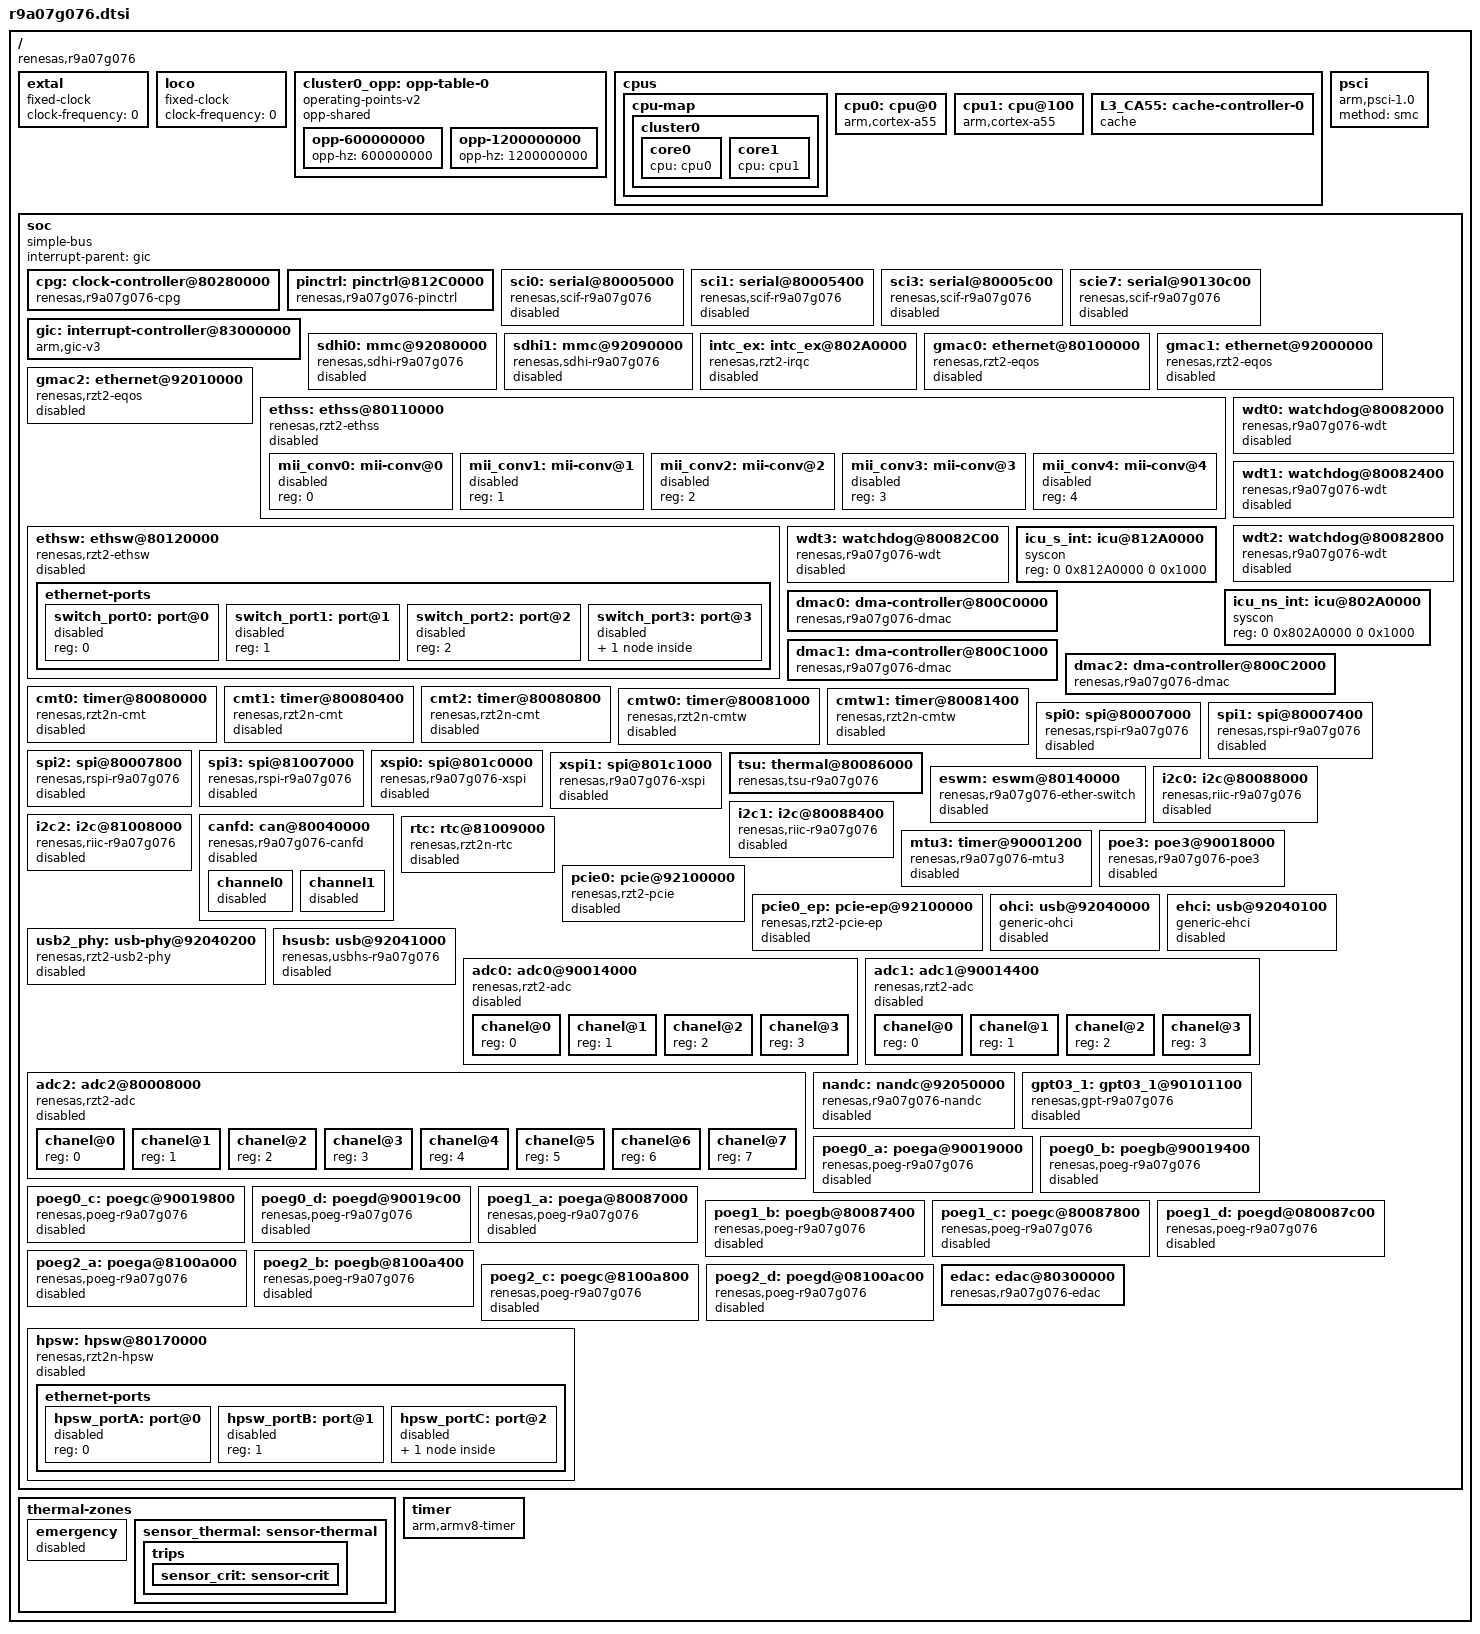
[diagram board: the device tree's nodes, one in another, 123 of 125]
// SPDX-License-Identifier: (GPL-2.0-only OR BSD-2-Clause)
/*
 * Device Tree Source for the RZ/T2N SoC
 *
 * Copyright (C) 2024 Renesas Electronics Corp.
 */

#include <dt-bindings/interrupt-controller/arm-gic.h>
#include <dt-bindings/clock/renesas,r9a07g076-cpg.h>

/ {
	compatible = "renesas,r9a07g076";
	#address-cells = <2>;
	#size-cells = <2>;

	extal: extal {
		compatible = "fixed-clock";
		#clock-cells = <0>;
		/* This value must be overridden by the board */
		clock-frequency = <0>;
	};

	loco: loco {
		compatible = "fixed-clock";
		#clock-cells = <0>;
		/* This value must be overridden by the board */
		clock-frequency = <0>;
	};

	cluster0_opp: opp-table-0 {
		compatible = "operating-points-v2";
		opp-shared;

		opp-600000000 {
			opp-hz = /bits/ 64 <600000000>;
		};
		opp-1200000000 {
			opp-hz = /bits/ 64 <1200000000>;
		};
	};

	cpus {
		#address-cells = <1>;
		#size-cells = <0>;

		cpu-map {
			cluster0 {
				core0 {
					cpu = <&cpu0>;
				};
				core1 {
					cpu = <&cpu1>;
				};
			};
		};

		cpu0: cpu@0 {
			compatible = "arm,cortex-a55";
			reg = <0>;
			device_type = "cpu";
			next-level-cache = <&L3_CA55>;
			enable-method = "psci";
			clocks = <&cpg CPG_MOD R9A07G076_CA55C0_CLK>;
			operating-points-v2 = <&cluster0_opp>;
		};

		cpu1: cpu@100 {
			compatible = "arm,cortex-a55";
			reg = <0x100>;
			device_type = "cpu";
			next-level-cache = <&L3_CA55>;
			enable-method = "psci";
			clocks = <&cpg CPG_MOD R9A07G076_CA55C1_CLK>;
			operating-points-v2 = <&cluster0_opp>;
		};

		L3_CA55: cache-controller-0 {
			compatible = "cache";
			cache-unified;
			cache-size = <0x40000>;
		};
	};

	psci {
		compatible = "arm,psci-1.0", "arm,psci-0.2";
		method = "smc";
	};

	soc: soc {
		compatible = "simple-bus";
		interrupt-parent = <&gic>;
		#address-cells = <2>;
		#size-cells = <2>;
		ranges;

		cpg: clock-controller@80280000 {
			compatible = "renesas,r9a07g076-cpg";
			reg = <0 0x80280000 0 0x1000>,
			      <0 0x81280000 0 0x9000>;
			clocks = <&extal>, <&loco>;
			clock-names = "extal", "loco";
			#clock-cells = <2>;
			#reset-cells = <1>;
			#power-domain-cells = <0>;
		};

		pinctrl: pinctrl@812C0000 {
			compatible = "renesas,r9a07g076-pinctrl";
			reg = <0 0x802C0000 0 0x2000>,
			      <0 0x812C0000 0 0x2000>;
			gpio-controller;
			#gpio-cells = <2>;
			gpio-ranges = <&pinctrl 0 0 201>;
		};

		sci0: serial@80005000 {
			compatible = "renesas,scif-r9a07g076",
				     "renesas,rz-rscif";
			reg = <0 0x80005000 0 0x400>;
			interrupts = <GIC_SPI 465 IRQ_TYPE_LEVEL_HIGH>,
				     <GIC_SPI 466 IRQ_TYPE_EDGE_RISING>,
				     <GIC_SPI 467 IRQ_TYPE_EDGE_RISING>,
				     <GIC_SPI 468 IRQ_TYPE_LEVEL_HIGH>;
			interrupt-names = "eri", "rxi", "txi", "tei";
			clocks = <&cpg CPG_MOD R9A07G076_SCI0_CLK>;
			clock-names = "fck";
			power-domains = <&cpg>;
			status = "disabled";
		};

		sci1: serial@80005400 {
			compatible = "renesas,scif-r9a07g076",
				     "renesas,rz-rscif";
			reg = <0 0x80005400 0 0x400>;
			interrupts = <GIC_SPI 469 IRQ_TYPE_LEVEL_HIGH>,
				     <GIC_SPI 470 IRQ_TYPE_EDGE_RISING>,
				     <GIC_SPI 471 IRQ_TYPE_EDGE_RISING>,
				     <GIC_SPI 472 IRQ_TYPE_LEVEL_HIGH>;
			interrupt-names = "eri", "rxi", "txi", "tei";
			clocks = <&cpg CPG_MOD R9A07G076_SCI1_CLK>;
			clock-names = "fck";
			power-domains = <&cpg>;
			status = "disabled";
		};

		sci3: serial@80005c00 {
			compatible = "renesas,scif-r9a07g076",
				     "renesas,rz-rscif";
			reg = <0 0x80005c00 0 0x400>;
			interrupts = <GIC_SPI 477 IRQ_TYPE_LEVEL_HIGH>,
				     <GIC_SPI 478 IRQ_TYPE_EDGE_RISING>,
				     <GIC_SPI 479 IRQ_TYPE_EDGE_RISING>,
				     <GIC_SPI 480 IRQ_TYPE_LEVEL_HIGH>;
			interrupt-names = "eri", "rxi", "txi", "tei";
			clocks = <&cpg CPG_MOD R9A07G076_SCI3_CLK>;
			clock-names = "fck";
			power-domains = <&cpg>;
			status = "disabled";
		};

		scie7: serial@90130c00 {
			compatible = "renesas,scif-r9a07g076",
				     "renesas,rz-rscif";
			reg = <0 0x90130c00 0 0x400>;
			interrupts = <GIC_SPI 600 IRQ_TYPE_LEVEL_HIGH>,
				     <GIC_SPI 601 IRQ_TYPE_EDGE_RISING>,
				     <GIC_SPI 602 IRQ_TYPE_EDGE_RISING>,
				     <GIC_SPI 603 IRQ_TYPE_LEVEL_HIGH>;
			interrupt-names = "eri", "rxi", "txi", "tei";
			clocks = <&cpg CPG_MOD R9A07G076_SCIE7_CLK>;
			clock-names = "fck";
			power-domains = <&cpg>;
			status = "disabled";
		};

		gic: interrupt-controller@83000000 {
			compatible = "arm,gic-v3";
			#interrupt-cells = <3>;
			#address-cells = <0>;
			interrupt-controller;
			reg = <0x0 0x83000000 0 0x40000>,
			      <0x0 0x83040000 0 0x160000>;
			interrupts = <GIC_PPI 9 IRQ_TYPE_LEVEL_LOW>;
		};

		sdhi0: mmc@92080000 {
			compatible = "renesas,sdhi-r9a07g076";
			reg = <0x0 0x92080000 0 0x10000>,
			      <0x0 0x8129B000 0 0x4>;
			interrupts = <GIC_SPI 604 IRQ_TYPE_LEVEL_HIGH>,
				     <GIC_SPI 605 IRQ_TYPE_LEVEL_HIGH>;
			clocks = <&cpg CPG_MOD R9A07G076_SDHI0_CLK>;
			clock-names = "clk";
			power-domains = <&cpg>;
			status = "disabled";
		};

		sdhi1: mmc@92090000 {
			compatible = "renesas,sdhi-r9a07g076";
			reg = <0x0 0x92090000 0 0x10000>,
			      <0x0 0x8129B004 0 0x4>;
			interrupts = <GIC_SPI 606 IRQ_TYPE_LEVEL_HIGH>,
				     <GIC_SPI 607 IRQ_TYPE_LEVEL_HIGH>;
			clocks = <&cpg CPG_MOD R9A07G076_SDHI1_CLK>;
			clock-names = "clk";
			power-domains = <&cpg>;
			status = "disabled";
		};

		intc_ex: intc_ex@802A0000 {
			compatible = "renesas,rzt2-irqc";
			#interrupt-cells = <2>;
			interrupt-controller;
			reg = <0x0 0x802A0000 0 0x1000>,
			      <0x0 0x812A0000 0 0x1000>;
			interrupts = <GIC_SPI 16 IRQ_TYPE_EDGE_RISING>,
				     <GIC_SPI 17 IRQ_TYPE_EDGE_RISING>,
				     <GIC_SPI 18 IRQ_TYPE_EDGE_RISING>,
				     <GIC_SPI 19 IRQ_TYPE_EDGE_RISING>,
				     <GIC_SPI 20 IRQ_TYPE_EDGE_RISING>,
				     <GIC_SPI 21 IRQ_TYPE_EDGE_RISING>,
				     <GIC_SPI 22 IRQ_TYPE_EDGE_RISING>,
				     <GIC_SPI 23 IRQ_TYPE_EDGE_RISING>,
				     <GIC_SPI 24 IRQ_TYPE_EDGE_RISING>,
				     <GIC_SPI 25 IRQ_TYPE_EDGE_RISING>,
				     <GIC_SPI 26 IRQ_TYPE_EDGE_RISING>,
				     <GIC_SPI 27 IRQ_TYPE_EDGE_RISING>,
				     <GIC_SPI 28 IRQ_TYPE_EDGE_RISING>,
				     <GIC_SPI 29 IRQ_TYPE_EDGE_RISING>,
				     <GIC_SPI 30 IRQ_TYPE_EDGE_RISING>,
				     <GIC_SPI 31 IRQ_TYPE_EDGE_RISING>;
			interrupt-names = "irq0", "irq1", "irq2", "irq3",
					  "irq4", "irq5", "irq6", "irq7",
					  "irq8", "irq9", "irq10", "irq11",
					  "irq12", "irq13", "irq14", "irq15";
			status = "disabled";
		};

		gmac0: ethernet@80100000 {
			compatible = "renesas,rzt2-eqos",
				     "snps,dwc-qos-ethernet-4.10";
			reg = <0 0x80100000 0 0x10000>;
			interrupts = <GIC_SPI 368 IRQ_TYPE_LEVEL_HIGH>,
				     <GIC_SPI 370 IRQ_TYPE_LEVEL_HIGH>,
				     <GIC_SPI 369 IRQ_TYPE_LEVEL_HIGH>;
			interrupt-names = "macirq", "eth_wake_irq", "eth_lpi";
			clocks = <&cpg CPG_MOD R9A07G076_GMAC0_CLK>;
			clock-names = "clk";
			ethsw_ptp_timer = <0 0>; /* GMAC0 PTP use ETHSW timer 0*/
			resets = <&cpg R9A07G076_GMAC0_PCLKH_RST>,
				 <&cpg R9A07G076_GMAC0_PCLKM_RST>;
			reset-names = "reset_h", "reset_m";
			#address-cells = <1>;
			#size-cells = <0>;
			status = "disabled";
			snps,write-requests = <15>;
			snps,read-requests = <15>;
			snps,burst-map = <0x7>;
		};

		gmac1: ethernet@92000000 {
			compatible = "renesas,rzt2-eqos",
				     "snps,dwc-qos-ethernet-4.10";
			reg = <0 0x92000000 0 0x10000>;
			interrupts = <GIC_SPI 387 IRQ_TYPE_LEVEL_HIGH>,
				     <GIC_SPI 389 IRQ_TYPE_LEVEL_HIGH>,
				     <GIC_SPI 388 IRQ_TYPE_LEVEL_HIGH>;
			interrupt-names = "macirq", "eth_wake_irq", "eth_lpi";
			clocks = <&cpg CPG_MOD R9A07G076_GMAC1_CLK>;
			clock-names = "clk";
			ethsw_ptp_timer = <1 0>; /* GMAC1 PTP use ETHSW timer 0*/
			resets = <&cpg R9A07G076_GMAC1_PCLKAH_RST>,
				 <&cpg R9A07G076_GMAC1_PCLKAM_RST>;
			reset-names = "reset_h", "reset_m";
			#address-cells = <1>;
			#size-cells = <0>;
			status = "disabled";
			snps,write-requests = <15>;
			snps,read-requests = <15>;
			snps,burst-map = <0x7>;
		};

		gmac2: ethernet@92010000 {
			compatible = "renesas,rzt2-eqos",
				     "snps,dwc-qos-ethernet-4.10";
			reg = <0 0x92010000 0 0x10000>;
			interrupts = <GIC_SPI 406 IRQ_TYPE_LEVEL_HIGH>,
				     <GIC_SPI 408 IRQ_TYPE_LEVEL_HIGH>,
				     <GIC_SPI 407 IRQ_TYPE_LEVEL_HIGH>;
			interrupt-names = "macirq", "eth_wake_irq", "eth_lpi";
			clocks = <&cpg CPG_MOD R9A07G076_GMAC2_CLK>;
			clock-names = "clk";
			ethsw_ptp_timer = <2 0>; /* GMAC2 PTP use ETHSW timer 0*/
			resets = <&cpg R9A07G076_GMAC2_PCLKAH_RST>,
				 <&cpg R9A07G076_GMAC2_PCLKAM_RST>;
			reset-names = "reset_h", "reset_m";
			#address-cells = <1>;
			#size-cells = <0>;
			status = "disabled";
			snps,write-requests = <15>;
			snps,read-requests = <15>;
			snps,burst-map = <0x7>;
		};

		ethss: ethss@80110000 {
			compatible = "renesas,rzt2-ethss";
			#address-cells = <1>;
			#size-cells = <0>;
			reg =  <0 0x80110000 0 0x10000>;
			clocks = <&cpg CPG_MOD R9A07G076_ETHSS_CLK>;
			resets = <&cpg R9A07G076_ETHSS_RST>,
				 <&cpg R9A07G076_MII_RST>;
			reset-names = "reset_ethss", "reset_conv";
			power-domains = <&cpg>;
			status = "disabled";

			mii_conv0: mii-conv@0 {
				reg = <0>;
				status = "disabled";
			};

			mii_conv1: mii-conv@1 {
				reg = <1>;
				status = "disabled";
			};

			mii_conv2: mii-conv@2 {
				reg = <2>;
				status = "disabled";
			};

			mii_conv3: mii-conv@3 {
				reg = <3>;
				status = "disabled";
			};

			mii_conv4: mii-conv@4 {
				reg = <4>;
				status = "disabled";
			};
		};

		ethsw: ethsw@80120000 {
			compatible = "renesas,rzt2-ethsw";
			reg =  <0 0x80120000 0 0x10000>;
			clocks = <&cpg CPG_MOD R9A07G076_ETHSW_CLK>;
			resets = <&cpg R9A07G076_ETHSW_RST>;
			power-domains = <&cpg>;
			interrupts = <GIC_SPI 425 IRQ_TYPE_LEVEL_HIGH>;
			interrupt-names = "ethsw_intr";
			ethsw_ptp_timer = <0>;	/* ETHSW PTP use ETHSW timer 0*/
			status = "disabled";

			ethernet-ports {
				#address-cells = <1>;
				#size-cells = <0>;

				switch_port0: port@0 {
					reg = <0>;
					status = "disabled";
				};

				switch_port1: port@1 {
					reg = <1>;
					status = "disabled";
				};

				switch_port2: port@2 {
					reg = <2>;
					status = "disabled";
				};

				switch_port3: port@3 {
					reg = <3>;
					ethernet = <&gmac0>;
					label = "cpu";
					phy-mode = "internal";
					status = "disabled";
					fixed-link {
						speed = <1000>;
						full-duplex;
					};
				};
			};
		};

		wdt0: watchdog@80082000 {
			compatible = "renesas,r9a07g076-wdt";
			reg = <0 0x80082000 0 0x400>,
			      <0 0x81295100 0 0x04>;
			reg-names = "wdt", "dbg";
			clocks = <&cpg CPG_CORE R9A07G076_PCLKL>;
			clock-names = "pclkl";
			power-domains = <&cpg>;
			renesas,syscon-perierr-error = <&icu_ns_int>;
			status = "disabled";
		};

		wdt1: watchdog@80082400 {
			compatible = "renesas,r9a07g076-wdt";
			reg = <0 0x80082400 0 0x400>,
			      <0 0x81295104 0 0x04>;
			reg-names = "wdt", "dbg";
			clocks = <&cpg CPG_CORE R9A07G076_PCLKL>;
			clock-names = "pclkl";
			power-domains = <&cpg>;
			renesas,syscon-perierr-error = <&icu_ns_int>;
			status = "disabled";
		};

		wdt2: watchdog@80082800 {
			compatible = "renesas,r9a07g076-wdt";
			reg = <0 0x80082800 0 0x400>,
			      <0 0x81295108 0 0x04>;
			reg-names = "wdt", "dbg";
			clocks = <&cpg CPG_CORE R9A07G076_PCLKL>;
			clock-names = "pclkl";
			power-domains = <&cpg>;
			renesas,syscon-perierr-error = <&icu_ns_int>;
			status = "disabled";
		};

		wdt3: watchdog@80082C00 {
			compatible = "renesas,r9a07g076-wdt";
			reg = <0 0x80082C00 0 0x400>,
			      <0 0x8129510C 0 0x04>;
			reg-names = "wdt", "dbg";
			clocks = <&cpg CPG_CORE R9A07G076_PCLKL>;
			clock-names = "pclkl";
			power-domains = <&cpg>;
			renesas,syscon-perierr-error = <&icu_ns_int>;
			status = "disabled";
		};

		icu_s_int: icu@812A0000 {
			compatible = "syscon";
			reg = <0 0x812A0000 0 0x1000>;
		};

		icu_ns_int: icu@802A0000 {
			compatible = "syscon";
			reg = <0 0x802A0000 0 0x1000>;
		};

		dmac0: dma-controller@800C0000 {
			compatible = "renesas,r9a07g076-dmac";
			reg = <0 0x800c0000 0 0x1000>;
			interrupts = <GIC_SPI 32 IRQ_TYPE_EDGE_RISING>,
				     <GIC_SPI 33 IRQ_TYPE_EDGE_RISING>,
				     <GIC_SPI 34 IRQ_TYPE_EDGE_RISING>,
				     <GIC_SPI 35 IRQ_TYPE_EDGE_RISING>,
				     <GIC_SPI 36 IRQ_TYPE_EDGE_RISING>,
				     <GIC_SPI 37 IRQ_TYPE_EDGE_RISING>,
				     <GIC_SPI 38 IRQ_TYPE_EDGE_RISING>,
				     <GIC_SPI 39 IRQ_TYPE_EDGE_RISING>,
				     <GIC_SPI 40 IRQ_TYPE_EDGE_RISING>,
				     <GIC_SPI 41 IRQ_TYPE_EDGE_RISING>,
				     <GIC_SPI 42 IRQ_TYPE_EDGE_RISING>,
				     <GIC_SPI 43 IRQ_TYPE_EDGE_RISING>,
				     <GIC_SPI 44 IRQ_TYPE_EDGE_RISING>,
				     <GIC_SPI 45 IRQ_TYPE_EDGE_RISING>,
				     <GIC_SPI 46 IRQ_TYPE_EDGE_RISING>,
				     <GIC_SPI 47 IRQ_TYPE_EDGE_RISING>;
			interrupt-names = "ch0", "ch1", "ch2", "ch3",
					  "ch4", "ch5", "ch6", "ch7",
					  "ch8", "ch9", "ch10", "ch11",
					  "ch12", "ch13", "ch14", "ch15";
			#dma-cells = <1>;
			dma-channels = <16>;
			renesas,icu = <&intc_ex 0>;
		};

		dmac1: dma-controller@800C1000 {
			compatible = "renesas,r9a07g076-dmac";
			reg = <0 0x800c1000 0 0x1000>;
			interrupts = <GIC_SPI 48 IRQ_TYPE_EDGE_RISING>,
				     <GIC_SPI 49 IRQ_TYPE_EDGE_RISING>,
				     <GIC_SPI 50 IRQ_TYPE_EDGE_RISING>,
				     <GIC_SPI 51 IRQ_TYPE_EDGE_RISING>,
				     <GIC_SPI 52 IRQ_TYPE_EDGE_RISING>,
				     <GIC_SPI 53 IRQ_TYPE_EDGE_RISING>,
				     <GIC_SPI 54 IRQ_TYPE_EDGE_RISING>,
				     <GIC_SPI 55 IRQ_TYPE_EDGE_RISING>,
				     <GIC_SPI 56 IRQ_TYPE_EDGE_RISING>,
				     <GIC_SPI 57 IRQ_TYPE_EDGE_RISING>,
				     <GIC_SPI 58 IRQ_TYPE_EDGE_RISING>,
				     <GIC_SPI 59 IRQ_TYPE_EDGE_RISING>,
				     <GIC_SPI 60 IRQ_TYPE_EDGE_RISING>,
				     <GIC_SPI 61 IRQ_TYPE_EDGE_RISING>,
				     <GIC_SPI 62 IRQ_TYPE_EDGE_RISING>,
				     <GIC_SPI 63 IRQ_TYPE_EDGE_RISING>;
			interrupt-names = "ch0", "ch1", "ch2", "ch3",
					  "ch4", "ch5", "ch6", "ch7",
					  "ch8", "ch9", "ch10", "ch11",
					  "ch12", "ch13", "ch14", "ch15";
			#dma-cells = <1>;
			dma-channels = <16>;
			renesas,icu = <&intc_ex 1>;
		};

		dmac2: dma-controller@800C2000 {
			compatible = "renesas,r9a07g076-dmac";
			reg = <0 0x800c2000 0 0x1000>;
			interrupts = <GIC_SPI 64 IRQ_TYPE_EDGE_RISING>,
				     <GIC_SPI 65 IRQ_TYPE_EDGE_RISING>,
				     <GIC_SPI 66 IRQ_TYPE_EDGE_RISING>,
				     <GIC_SPI 67 IRQ_TYPE_EDGE_RISING>,
				     <GIC_SPI 68 IRQ_TYPE_EDGE_RISING>,
				     <GIC_SPI 69 IRQ_TYPE_EDGE_RISING>,
				     <GIC_SPI 70 IRQ_TYPE_EDGE_RISING>,
				     <GIC_SPI 71 IRQ_TYPE_EDGE_RISING>,
				     <GIC_SPI 72 IRQ_TYPE_EDGE_RISING>,
				     <GIC_SPI 73 IRQ_TYPE_EDGE_RISING>,
				     <GIC_SPI 74 IRQ_TYPE_EDGE_RISING>,
				     <GIC_SPI 75 IRQ_TYPE_EDGE_RISING>,
				     <GIC_SPI 76 IRQ_TYPE_EDGE_RISING>,
				     <GIC_SPI 77 IRQ_TYPE_EDGE_RISING>,
				     <GIC_SPI 78 IRQ_TYPE_EDGE_RISING>,
				     <GIC_SPI 79 IRQ_TYPE_EDGE_RISING>;
			interrupt-names = "ch0", "ch1", "ch2", "ch3",
					  "ch4", "ch5", "ch6", "ch7",
					  "ch8", "ch9", "ch10", "ch11",
					  "ch12", "ch13", "ch14", "ch15";
			#dma-cells = <1>;
			dma-channels = <16>;
			renesas,icu = <&intc_ex 2>;
		};

		cmt0: timer@80080000 {
			compatible = "renesas,rzt2n-cmt";
			reg = <0 0x80080000 0 0x400>;
			interrupts = <GIC_SPI 349 IRQ_TYPE_EDGE_RISING>,
				     <GIC_SPI 350 IRQ_TYPE_EDGE_RISING>;
			clocks = <&cpg CPG_MOD R9A07G076_CMT0_CLK>;
			clock-names = "fck0";
			power-domains = <&cpg>;
			status = "disabled";
		};

		cmt1: timer@80080400 {
			compatible = "renesas,rzt2n-cmt";
			reg = <0 0x80080400 0 0x400>;
			interrupts = <GIC_SPI 351 IRQ_TYPE_EDGE_RISING>,
				     <GIC_SPI 352 IRQ_TYPE_EDGE_RISING>;
			clocks = <&cpg CPG_MOD R9A07G076_CMT1_CLK>;
			clock-names = "fck0";
			power-domains = <&cpg>;
			status = "disabled";
		};

		cmt2: timer@80080800 {
			compatible = "renesas,rzt2n-cmt";
			reg = <0 0x80080800 0 0x400>;
			interrupts = <GIC_SPI 353 IRQ_TYPE_EDGE_RISING>,
				     <GIC_SPI 354 IRQ_TYPE_EDGE_RISING>;
			clocks = <&cpg CPG_MOD R9A07G076_CMT2_CLK>;
			clock-names = "fck0";
			power-domains = <&cpg>;
			status = "disabled";
		};

		cmtw0: timer@80081000 {
			compatible = "renesas,rzt2n-cmtw";
			reg = <0 0x80081000 0 0x400>;
			interrupts = <GIC_SPI 355 IRQ_TYPE_EDGE_RISING>;
			clocks = <&cpg CPG_MOD R9A07G076_CMTW0_CLK>;
			clock-names = "fck0";
			power-domains = <&cpg>;
			status = "disabled";
		};

		cmtw1: timer@80081400 {
			compatible = "renesas,rzt2n-cmtw";
			reg = <0 0x80081400 0 0x400>;
			interrupts = <GIC_SPI 360 IRQ_TYPE_EDGE_RISING>;
			clocks = <&cpg CPG_MOD R9A07G076_CMTW1_CLK>;
			clock-names = "fck0";
			power-domains = <&cpg>;
			status = "disabled";
		};

		spi0: spi@80007000 {
			compatible = "renesas,rspi-r9a07g076";
			reg = <0 0x80007000 0 0x100>;
			interrupts = <GIC_SPI 509 IRQ_TYPE_EDGE_RISING>,
				     <GIC_SPI 510 IRQ_TYPE_EDGE_RISING>,
				     <GIC_SPI 512 IRQ_TYPE_LEVEL_HIGH>;
			interrupt-names = "rx", "tx", "error";
			clocks = <&cpg CPG_MOD R9A07G076_SPI0_CLK>;
			power-domains = <&cpg>;
			num-cs = <1>;
			dmas = <&dmac0 0x25FE>, <&dmac0 0x25FD>;
			dma-names = "tx", "rx";
			#address-cells = <1>;
			#size-cells = <0>;
			status = "disabled";
		};

		spi1: spi@80007400 {
			compatible = "renesas,rspi-r9a07g076";
			reg = <0 0x80007400 0 0x100>;
			interrupts = <GIC_SPI 514 IRQ_TYPE_EDGE_RISING>,
				     <GIC_SPI 515 IRQ_TYPE_EDGE_RISING>,
				     <GIC_SPI 517 IRQ_TYPE_LEVEL_HIGH>;
			interrupt-names = "rx", "tx", "error";
			clocks = <&cpg CPG_MOD R9A07G076_SPI1_CLK>;
			power-domains = <&cpg>;
			num-cs = <1>;
			dmas = <&dmac0 0x2603>, <&dmac0 0x2602>;
			dma-names = "tx", "rx";
			#address-cells = <1>;
			#size-cells = <0>;
			status = "disabled";
		};

		spi2: spi@80007800 {
			compatible = "renesas,rspi-r9a07g076";
			reg = <0 0x80007800 0 0x100>;
			interrupts = <GIC_SPI 519 IRQ_TYPE_EDGE_RISING>,
				     <GIC_SPI 520 IRQ_TYPE_EDGE_RISING>,
				     <GIC_SPI 522 IRQ_TYPE_LEVEL_HIGH>;
			interrupt-names = "rx", "tx", "error";
			clocks = <&cpg CPG_MOD R9A07G076_SPI2_CLK>;
			power-domains = <&cpg>;
			num-cs = <1>;
			dmas = <&dmac0 0x2608>, <&dmac0 0x2607>;
			dma-names = "tx", "rx";
			#address-cells = <1>;
			#size-cells = <0>;
			status = "disabled";
		};

		spi3: spi@81007000 {
			compatible = "renesas,rspi-r9a07g076";
			reg = <0 0x81007000 0 0x100>;
			interrupts = <GIC_SPI 524 IRQ_TYPE_EDGE_RISING>,
				     <GIC_SPI 525 IRQ_TYPE_EDGE_RISING>,
				     <GIC_SPI 527 IRQ_TYPE_LEVEL_HIGH>;
			interrupt-names = "rx", "tx", "error";
			clocks = <&cpg CPG_MOD R9A07G076_SPI3_CLK>;
			power-domains = <&cpg>;
			num-cs = <1>;
			#address-cells = <1>;
			#size-cells = <0>;
			status = "disabled";
		};

		xspi0: spi@801c0000 {
			compatible = "renesas,r9a07g076-xspi",
				     "renesas,r9a09g047-xspi";
			reg = <0 0x801c0000 0 0x1000>,
			      <0 0x40000000 0 0x10000000>;
			reg-names = "regs", "dirmap";
			resets = <&cpg R9A07G076_xSPI0_RST>;
			power-domains = <&cpg>;
			#address-cells = <1>;
			#size-cells = <0>;
			status = "disabled";
		};

		xspi1: spi@801c1000 {
			compatible = "renesas,r9a07g076-xspi",
				     "renesas,r9a09g047-xspi";
			reg = <0 0x801c1000 0 0x1000>,
			      <0 0x50000000 0 0x10000000>;
			reg-names = "regs", "dirmap";
			resets = <&cpg R9A07G076_xSPI1_RST>;
			power-domains = <&cpg>;
			#address-cells = <1>;
			#size-cells = <0>;
			status = "disabled";
		};

		tsu: thermal@80086000 {
			compatible = "renesas,tsu-r9a07g076";
			reg = <0 0x80086000 0 0x1000>;
			clocks = <&cpg CPG_MOD R9A07G076_TSU_CLK>;
			clock-names = "tsu_clk";
			#thermal-sensor-cells = <1>;
		};

		eswm: eswm@80140000 {
			compatible = "renesas,r9a07g076-ether-switch";
			reg = <0 0x80140000 0 0x30000>;
			reg-names = "base";
			interrupts = <GIC_SPI 456 IRQ_TYPE_LEVEL_HIGH>,
				     <GIC_SPI 457 IRQ_TYPE_LEVEL_HIGH>,
				     <GIC_SPI 458 IRQ_TYPE_LEVEL_HIGH>,
				     <GIC_SPI 459 IRQ_TYPE_LEVEL_HIGH>,
				     <GIC_SPI 460 IRQ_TYPE_LEVEL_HIGH>,
				     <GIC_SPI 630 IRQ_TYPE_LEVEL_HIGH>,
				     <GIC_SPI 631 IRQ_TYPE_LEVEL_HIGH>,
				     <GIC_SPI 632 IRQ_TYPE_LEVEL_HIGH>,
				     <GIC_SPI 633 IRQ_TYPE_LEVEL_HIGH>,
				     <GIC_SPI 634 IRQ_TYPE_LEVEL_HIGH>,
				     <GIC_SPI 635 IRQ_TYPE_LEVEL_HIGH>,
				     <GIC_SPI 636 IRQ_TYPE_LEVEL_HIGH>,
				     <GIC_SPI 637 IRQ_TYPE_LEVEL_HIGH>,
				     <GIC_SPI 638 IRQ_TYPE_LEVEL_HIGH>,
				     <GIC_SPI 639 IRQ_TYPE_LEVEL_HIGH>;
			interrupt-names = "gptp", "mfwd",
					  "coma", "eth0",
					  "eth1", "gwca0_rxtx0",
					  "gwca0_rxtx1", "gwca0_rxtx2",
					  "gwca0_rxtx3", "gwca0_rxtx4",
					  "gwca0_rxtx5", "gwca0_rxtx6",
					  "gwca0_rxtx7", "gwca0_rxts0",
					  "gwca0_rxts1";
			#address-cells = <1>;
			#size-cells = <0>;
			eswm_ptp_timer = <1>;	/*ESWM PTP use ESWM timer 1*/
			clocks = <&cpg CPG_MOD R9A07G076_ESWM_CLK>;
			resets = <&cpg R9A07G076_ESWM_RST>;
			power-domains = <&cpg>;
			status = "disabled";
		};

		i2c0: i2c@80088000 {
			#address-cells = <1>;
			#size-cells = <0>;
			compatible = "renesas,riic-r9a07g076";
			reg = <0 0x80088000 0 0x20>;
			interrupts = <GIC_SPI 489 IRQ_TYPE_LEVEL_HIGH>,
				     <GIC_SPI 490 IRQ_TYPE_EDGE_RISING>,
				     <GIC_SPI 491 IRQ_TYPE_EDGE_RISING>,
				     <GIC_SPI 492 IRQ_TYPE_LEVEL_HIGH>;
			interrupt-names = "eei", "rxi", "txi", "tei";
			clocks = <&cpg CPG_MOD R9A07G076_IIC0_CLK>;
			clock-frequency = <100000>;
			power-domains = <&cpg>;
			status = "disabled";
		};

		i2c1: i2c@80088400 {
			#address-cells = <1>;
			#size-cells = <0>;
			compatible = "renesas,riic-r9a07g076";
			reg = <0 0x80088400 0 0x20>;
			interrupts = <GIC_SPI 493 IRQ_TYPE_LEVEL_HIGH>,
				     <GIC_SPI 494 IRQ_TYPE_EDGE_RISING>,
				     <GIC_SPI 495 IRQ_TYPE_EDGE_RISING>,
				     <GIC_SPI 496 IRQ_TYPE_LEVEL_HIGH>;
			interrupt-names = "eei", "rxi", "txi", "tei";
			clocks = <&cpg CPG_MOD R9A07G076_IIC1_CLK>;
			clock-frequency = <100000>;
			power-domains = <&cpg>;
			status = "disabled";
		};

		i2c2: i2c@81008000 {
			#address-cells = <1>;
			#size-cells = <0>;
			compatible = "renesas,riic-r9a07g076";
			reg = <0 0x81008000 0 0x20>;
			interrupts = <GIC_SPI 497 IRQ_TYPE_LEVEL_HIGH>,
				     <GIC_SPI 498 IRQ_TYPE_EDGE_RISING>,
				     <GIC_SPI 499 IRQ_TYPE_EDGE_RISING>,
				     <GIC_SPI 500 IRQ_TYPE_LEVEL_HIGH>;
			interrupt-names = "eei", "rxi", "txi", "tei";
			clocks = <&cpg CPG_MOD R9A07G076_IIC2_CLK>;
			clock-frequency = <100000>;
			power-domains = <&cpg>;
			status = "disabled";
		};

		canfd: can@80040000 {
			compatible = "renesas,r9a07g076-canfd";
			reg = <0 0x80040000 0 0x20000>;
			interrupts =	<GIC_SPI 501 IRQ_TYPE_LEVEL_HIGH>,
					<GIC_SPI 502 IRQ_TYPE_LEVEL_HIGH>,
					<GIC_SPI 503 IRQ_TYPE_LEVEL_HIGH>,
					<GIC_SPI 504 IRQ_TYPE_LEVEL_HIGH>,
					<GIC_SPI 505 IRQ_TYPE_LEVEL_HIGH>,
					<GIC_SPI 506 IRQ_TYPE_LEVEL_HIGH>,
					<GIC_SPI 507 IRQ_TYPE_LEVEL_HIGH>,
					<GIC_SPI 508 IRQ_TYPE_LEVEL_HIGH>;
			interrupt-names = "ch0_trx", "ch0_err", "ch0_rec",
					  "ch1_trx", "ch1_err", "ch1_rec",
					  "g_recc", "g_err";
			clocks = <&cpg CPG_MOD R9A07G076_CANFD_CLK>,
				 <&cpg CPG_CORE R9A07G076_PCLKH>,
				 <&cpg CPG_CORE R9A07G076_CAN>;
			clock-names = "fck", "ram_clk", "can_clk";
			power-domains = <&cpg>;
			status = "disabled";

			channel0 {
				status = "disabled";
			};
			channel1 {
				status = "disabled";
			};
		};

		rtc: rtc@81009000 {
			compatible = "renesas,rzt2n-rtc";
			reg = <0 0x81009000 0 0x1000>;
			interrupts = <GIC_SPI 365 IRQ_TYPE_EDGE_RISING>,
				     <GIC_SPI 366 IRQ_TYPE_EDGE_RISING>,
				     <GIC_SPI 367 IRQ_TYPE_EDGE_RISING>;
			interrupt-names = "alarm", "carry", "periodic";
			clocks = <&cpg CPG_MOD R9A07G076_RTC_CLK>;
			clock-names = "rtc";
			power-domains = <&cpg>;
			status = "disabled";
		};

		mtu3: timer@90001200 {
			compatible = "renesas,r9a07g076-mtu3", "renesas,rz-mtu3";
			reg = <0 0x90001200 0 0xB00>;
			interrupts = <GIC_SPI 290 IRQ_TYPE_EDGE_RISING>,
				     <GIC_SPI 291 IRQ_TYPE_EDGE_RISING>,
				     <GIC_SPI 292 IRQ_TYPE_EDGE_RISING>,
				     <GIC_SPI 293 IRQ_TYPE_EDGE_RISING>,
				     <GIC_SPI 294 IRQ_TYPE_EDGE_RISING>,
				     <GIC_SPI 295 IRQ_TYPE_EDGE_RISING>,
				     <GIC_SPI 296 IRQ_TYPE_EDGE_RISING>,
				     <GIC_SPI 297 IRQ_TYPE_EDGE_RISING>,
				     <GIC_SPI 298 IRQ_TYPE_EDGE_RISING>,
				     <GIC_SPI 299 IRQ_TYPE_EDGE_RISING>,
				     <GIC_SPI 300 IRQ_TYPE_EDGE_RISING>,
				     <GIC_SPI 301 IRQ_TYPE_EDGE_RISING>,
				     <GIC_SPI 302 IRQ_TYPE_EDGE_RISING>,
				     <GIC_SPI 303 IRQ_TYPE_EDGE_RISING>,
				     <GIC_SPI 304 IRQ_TYPE_EDGE_RISING>,
				     <GIC_SPI 305 IRQ_TYPE_EDGE_RISING>,
				     <GIC_SPI 306 IRQ_TYPE_EDGE_RISING>,
				     <GIC_SPI 307 IRQ_TYPE_EDGE_RISING>,
				     <GIC_SPI 308 IRQ_TYPE_EDGE_RISING>,
				     <GIC_SPI 309 IRQ_TYPE_EDGE_RISING>,
				     <GIC_SPI 310 IRQ_TYPE_EDGE_RISING>,
				     <GIC_SPI 311 IRQ_TYPE_EDGE_RISING>,
				     <GIC_SPI 312 IRQ_TYPE_EDGE_RISING>,
				     <GIC_SPI 313 IRQ_TYPE_EDGE_RISING>,
				     <GIC_SPI 314 IRQ_TYPE_EDGE_RISING>,
				     <GIC_SPI 315 IRQ_TYPE_EDGE_RISING>,
				     <GIC_SPI 316 IRQ_TYPE_EDGE_RISING>,
				     <GIC_SPI 317 IRQ_TYPE_EDGE_RISING>,
				     <GIC_SPI 318 IRQ_TYPE_EDGE_RISING>,
				     <GIC_SPI 319 IRQ_TYPE_EDGE_RISING>,
				     <GIC_SPI 320 IRQ_TYPE_EDGE_RISING>,
				     <GIC_SPI 321 IRQ_TYPE_EDGE_RISING>,
				     <GIC_SPI 322 IRQ_TYPE_EDGE_RISING>,
				     <GIC_SPI 323 IRQ_TYPE_EDGE_RISING>,
				     <GIC_SPI 324 IRQ_TYPE_EDGE_RISING>,
				     <GIC_SPI 325 IRQ_TYPE_EDGE_RISING>,
				     <GIC_SPI 326 IRQ_TYPE_EDGE_RISING>,
				     <GIC_SPI 327 IRQ_TYPE_EDGE_RISING>,
				     <GIC_SPI 328 IRQ_TYPE_EDGE_RISING>,
				     <GIC_SPI 329 IRQ_TYPE_EDGE_RISING>,
				     <GIC_SPI 330 IRQ_TYPE_EDGE_RISING>,
				     <GIC_SPI 331 IRQ_TYPE_EDGE_RISING>,
				     <GIC_SPI 332 IRQ_TYPE_EDGE_RISING>;
			interrupt-names = "tgia0", "tgib0", "tgic0", "tgid0",
					  "tciv0", "tgie0", "tgif0",
					  "tgia1", "tgib1", "tciv1", "tciu1",
					  "tgia2", "tgib2", "tciv2", "tciu2",
					  "tgia3", "tgib3", "tgic3", "tgid3",
					  "tciv3",
					  "tgia4", "tgib4", "tgic4", "tgid4",
					  "tciv4",
					  "tgiu5", "tgiv5", "tgiw5",
					  "tgia6", "tgib6", "tgic6", "tgid6",
					  "tciv6",
					  "tgia7", "tgib7", "tgic7", "tgid7",
					  "tciv7",
					  "tgia8", "tgib8", "tgic8", "tgid8",
					  "tciv8";
			clocks = <&cpg CPG_MOD R9A07G076_MTU3_CLK>;
			clock-names = "fck";
			power-domains = <&cpg>;
			status = "disabled";
		};

		poe3: poe3@90018000 {
			compatible = "renesas,r9a07g076-poe3", "renesas,rz-poe3";
			reg = <0 0x90018000 0 0x42>;
			interrupts = <GIC_SPI 333 IRQ_TYPE_LEVEL_HIGH>,
				     <GIC_SPI 334 IRQ_TYPE_LEVEL_HIGH>,
				     <GIC_SPI 335 IRQ_TYPE_LEVEL_HIGH>,
				     <GIC_SPI 336 IRQ_TYPE_LEVEL_HIGH>;
			interrupt-names = "oei1", "oei2", "oei3", "oei4";
			clocks = <&cpg CPG_CORE R9A07G076_PCLKL>;
			clock-names = "pclkl";
			power-domains = <&cpg>;
			status = "disabled";
		};

		pcie0: pcie@92100000 {
			compatible = "renesas,rzt2-pcie";
			device_type = "pci";
			reg = <0 0x92100000 0 0x10000>,
			      <0 0x80292000 0 0x30>;
			clocks = <&cpg CPG_MOD R9A07G076_PCIE_CLK>;
			power-domains = <&cpg>;
			resets = <&cpg R9A07G076_PCIE_RST>;
			ranges = <0x02000000 0x0 0xA0000000 0x4 0x00000000 0x0 0x10000000>;
			dma-ranges = <0x02000000 0x0 0xC4000000 0x0 0xC4000000 0x0 0x3C000000>,
				     <0x42000000 0x2 0x40000000 0x2 0x40000000 0x0 0x40000000>;
			interrupts = <GIC_SPI 612 IRQ_TYPE_LEVEL_HIGH>,
				     <GIC_SPI 616 IRQ_TYPE_LEVEL_HIGH>;
			#interrupt-cells = <1>;
			interrupt-map-mask = <0 0 0 0>;
			interrupt-map = <0 0 0 0 &gic GIC_SPI 612 IRQ_TYPE_LEVEL_HIGH>;
			bus-range = <0x0 0xff>;
			linux,pci-domain = <0x0>;
			#address-cells = <3>;
			#size-cells = <2>;
			pcie,channel = <0>;
			status = "disabled";
		};

		pcie0_ep: pcie-ep@92100000 {
			compatible = "renesas,rzt2-pcie-ep";
			reg = <0x0 0x92100000 0x0 0x10000>,
			      <0x0 0x80292000 0x0 0x30>,
			      <0x4 0x00000000 0x1 0x00000000>,
			      <0x5 0x00000000 0x1 0x00000000>;
			reg-names = "apb-base0", "apb-base1", "memory0", "memory1";
			interrupts = <GIC_SPI 619 IRQ_TYPE_LEVEL_HIGH>,
				     <GIC_SPI 616 IRQ_TYPE_LEVEL_HIGH>;
			clocks = <&cpg CPG_MOD R9A07G076_PCIE_CLK>;
			power-domains = <&cpg>;
			resets = <&cpg R9A07G076_PCIE_RST>;
			pcie,channel = <0>;
			status = "disabled";
		};

		ohci: usb@92040000 {
			compatible = "generic-ohci";
			reg = <0 0x92040000 0 0x100>;
			interrupts = <GIC_SPI 461 IRQ_TYPE_LEVEL_HIGH>;
			clocks = <&cpg CPG_MOD R9A07G076_USB_CLK>;
			phys = <&usb2_phy 1>;
			phy-names = "usb";
			power-domains = <&cpg>;
			status = "disabled";
		};

		ehci: usb@92040100 {
			compatible = "generic-ehci";
			reg = <0 0x92040100 0 0x100>;
			interrupts = <GIC_SPI 461 IRQ_TYPE_LEVEL_HIGH>;
			clocks = <&cpg CPG_MOD R9A07G076_USB_CLK>;
			phys = <&usb2_phy 2>;
			phy-names = "usb";
			companion = <&ohci>;
			power-domains = <&cpg>;
			status = "disabled";
		};

		usb2_phy: usb-phy@92040200 {
			compatible = "renesas,rzt2-usb2-phy";
			reg = <0 0x92040200 0 0x700>;
			interrupts = <GIC_SPI 461 IRQ_TYPE_LEVEL_HIGH>;
			clocks = <&cpg CPG_MOD R9A07G076_USB_CLK>;
			#phy-cells = <1>;
			power-domains = <&cpg>;
			status = "disabled";
		};

		hsusb: usb@92041000 {
			compatible = "renesas,usbhs-r9a07g076",
				     "renesas,rzg2l-usbhs";
			reg = <0 0x92041000 0 0x2000>;
			interrupts = <GIC_SPI 462 IRQ_TYPE_LEVEL_HIGH>,
				     <GIC_SPI 463 IRQ_TYPE_LEVEL_HIGH>,
				     <GIC_SPI 464 IRQ_TYPE_LEVEL_HIGH>;
			clocks = <&cpg CPG_MOD R9A07G076_USB_CLK>;
			phys = <&usb2_phy 3>;
			phy-names = "usb";
			power-domains = <&cpg>;
			status = "disabled";
		};

		adc0: adc0@90014000 {
			compatible = "renesas,rzt2-adc";
			reg = <0 0x90014000 0 0x400>;
			interrupts = <GIC_SPI 553 IRQ_TYPE_EDGE_RISING>,
				     <GIC_SPI 554 IRQ_TYPE_EDGE_RISING>,
				     <GIC_SPI 555 IRQ_TYPE_EDGE_RISING>,
				     <GIC_SPI 556 IRQ_TYPE_LEVEL_HIGH>,
				     <GIC_SPI 557 IRQ_TYPE_LEVEL_HIGH>,
				     <GIC_SPI 661 IRQ_TYPE_EDGE_RISING>,
				     <GIC_SPI 662 IRQ_TYPE_EDGE_RISING>;
			interrupt-names = "adi", "gbadi", "gcadi",
					  "cmpai", "cmpbi", "wcmpm", "wcmpum";
			clocks = <&cpg CPG_MOD R9A07G076_ADC0_CLK>;
			power-domains = <&cpg>;
			status = "disabled";
			#address-cells = <1>;
			#size-cells = <0>;
			#io-channel-cells = <1>;
			renesas,max-channels = <4>;

			chanel@0 {
				reg = <0>;
			};
			chanel@1 {
				reg = <1>;
			};
			chanel@2 {
				reg = <2>;
			};
			chanel@3 {
				reg = <3>;
			};
		};

		adc1: adc1@90014400 {
			compatible = "renesas,rzt2-adc";
			reg = <0 0x90014400 0 0x400>;
			interrupts = <GIC_SPI 558 IRQ_TYPE_EDGE_RISING>,
				     <GIC_SPI 559 IRQ_TYPE_EDGE_RISING>,
				     <GIC_SPI 560 IRQ_TYPE_EDGE_RISING>,
				     <GIC_SPI 561 IRQ_TYPE_LEVEL_HIGH>,
				     <GIC_SPI 562 IRQ_TYPE_LEVEL_HIGH>,
				     <GIC_SPI 663 IRQ_TYPE_EDGE_RISING>,
				     <GIC_SPI 664 IRQ_TYPE_EDGE_RISING>;
			interrupt-names = "adi", "gbadi", "gcadi",
					  "cmpai", "cmpbi", "wcmpm", "wcmpum";
			clocks = <&cpg CPG_MOD R9A07G076_ADC1_CLK>;
			power-domains = <&cpg>;
			status = "disabled";
			#address-cells = <1>;
			#size-cells = <0>;
			#io-channel-cells = <1>;
			renesas,max-channels = <4>;

			chanel@0 {
				reg = <0>;
			};
			chanel@1 {
				reg = <1>;
			};
			chanel@2 {
				reg = <2>;
			};
			chanel@3 {
				reg = <3>;
			};
		};

		adc2: adc2@80008000 {
			compatible = "renesas,rzt2-adc";
			reg = <0 0x80008000 0 0x400>;
			interrupts = <GIC_SPI 563 IRQ_TYPE_EDGE_RISING>,
				     <GIC_SPI 564 IRQ_TYPE_EDGE_RISING>,
				     <GIC_SPI 565 IRQ_TYPE_EDGE_RISING>,
				     <GIC_SPI 566 IRQ_TYPE_LEVEL_HIGH>,
				     <GIC_SPI 576 IRQ_TYPE_LEVEL_HIGH>,
				     <GIC_SPI 665 IRQ_TYPE_EDGE_RISING>,
				     <GIC_SPI 666 IRQ_TYPE_EDGE_RISING>;
			interrupt-names = "adi", "gbadi", "gcadi",
					  "cmpai", "cmpbi", "wcmpm", "wcmpum";
			clocks = <&cpg CPG_MOD R9A07G076_ADC2_CLK>;
			power-domains = <&cpg>;
			status = "disabled";
			renesas,max-channels = <8>;
			#address-cells = <1>;
			#size-cells = <0>;
			#io-channel-cells = <1>;

			chanel@0 {
				reg = <0>;
			};
			chanel@1 {
				reg = <1>;
			};
			chanel@2 {
				reg = <2>;
			};
			chanel@3 {
				reg = <3>;
			};
			chanel@4 {
				reg = <4>;
			};
			chanel@5 {
				reg = <5>;
			};
			chanel@6 {
				reg = <6>;
			};
			chanel@7 {
				reg = <7>;
			};
		};

		nandc: nandc@92050000 {
			compatible = "renesas,r9a07g076-nandc";
			reg = <0 0x92050000 0 0x4000>,
			      <0 0x10100000 0 0x100000>,
			      <0 0x80297000 0 0x50>;
			interrupts = <GIC_SPI 628 IRQ_TYPE_LEVEL_HIGH>;
			clocks = <&cpg CPG_MOD R9A07G076_NANDC_CLK>,
				 <&cpg CPG_CORE R9A07G076_PCLKAM>,
				 <&cpg CPG_CORE R9A07G076_PCLKAL>;
			clock-names = "nf_clk", "sysclk", "busclk";
			resets = <&cpg R9A07G076_NANDC_SYSTEM_RST>,
				 <&cpg R9A07G076_NANDC_SLAVE_RST>,
				 <&cpg R9A07G076_NANDC_PROTECT_RST>;
			reset-names = "rst_sys", "rst_slave", "rst_prot";
			power-domains = <&cpg>;
			#address-cells = <1>;
			#size-cells = <0>;
			status = "disabled";
		};

		gpt03_1: gpt03_1@90101100 {
			compatible = "renesas,gpt-r9a07g076";
			reg =   <0 0x90101100 0 0x100>,
				<0 0x80290000 0 0x0c>;
			reg-names = "base1", "base2";
			#pwm-cells = <2>;
			interrupts = <GIC_SPI 709 IRQ_TYPE_EDGE_RISING>,
				     <GIC_SPI 710 IRQ_TYPE_EDGE_RISING>,
				     <GIC_SPI 177 IRQ_TYPE_EDGE_RISING>,
				     <GIC_SPI 178 IRQ_TYPE_EDGE_RISING>,
				     <GIC_SPI 179 IRQ_TYPE_EDGE_RISING>,
				     <GIC_SPI 180 IRQ_TYPE_EDGE_RISING>,
				     <GIC_SPI 181 IRQ_TYPE_EDGE_RISING>;
			interrupt-names = "adtrga", "adtrgb", "int0", "int1",
					  "int2", "int3", "int4";
			clocks = <&cpg CPG_MOD R9A07G076_GPT3_CLK>;
			power-domains = <&cpg>;
			renesas,syscon-perierr-error = <&icu_ns_int>,
						       <&icu_s_int>;
			status = "disabled";
		};

		poeg0_a: poega@90019000 {
			compatible = "renesas,poeg-r9a07g076";
			reg = <0 0x90019000 0 0x400>;
			interrupts = <GIC_SPI 337 IRQ_TYPE_LEVEL_HIGH>;
			clocks = <&cpg CPG_CORE R9A07G076_PCLKH>;
			power-domains = <&cpg>;
			llpp,disable-by-DSMIF-error;
			status = "disabled";
		};

		poeg0_b: poegb@90019400 {
			compatible = "renesas,poeg-r9a07g076";
			reg = <0 0x90019400 0 0x400>;
			interrupts = <GIC_SPI 338 IRQ_TYPE_LEVEL_HIGH>;
			clocks = <&cpg CPG_CORE R9A07G076_PCLKH>;
			power-domains = <&cpg>;
			llpp,disable-by-DSMIF-error;
			status = "disabled";
		};

		poeg0_c: poegc@90019800 {
			compatible = "renesas,poeg-r9a07g076";
			reg = <0 0x90019800 0 0x400>;
			interrupts = <GIC_SPI 339 IRQ_TYPE_LEVEL_HIGH>;
			clocks = <&cpg CPG_CORE R9A07G076_PCLKH>;
			power-domains = <&cpg>;
			llpp,disable-by-DSMIF-error;
			status = "disabled";
		};

		poeg0_d: poegd@90019c00 {
			compatible = "renesas,poeg-r9a07g076";
			reg = <0 0x90019c00 0 0x400>;
			interrupts = <GIC_SPI 340 IRQ_TYPE_LEVEL_HIGH>;
			clocks = <&cpg CPG_CORE R9A07G076_PCLKH>;
			power-domains = <&cpg>;
			llpp,disable-by-DSMIF-error;
			status = "disabled";
		};

		poeg1_a: poega@80087000 {
			compatible = "renesas,poeg-r9a07g076";
			reg = <0 0x80087000 0 0x400>;
			interrupts = <GIC_SPI 341 IRQ_TYPE_LEVEL_HIGH>;
			clocks = <&cpg CPG_CORE R9A07G076_PCLKL>;
			power-domains = <&cpg>;
			status = "disabled";
		};

		poeg1_b: poegb@80087400 {
			compatible = "renesas,poeg-r9a07g076";
			reg = <0 0x80087400 0 0x400>;
			interrupts = <GIC_SPI 342 IRQ_TYPE_LEVEL_HIGH>;
			clocks = <&cpg CPG_CORE R9A07G076_PCLKL>;
			power-domains = <&cpg>;
			status = "disabled";
		};

		poeg1_c: poegc@80087800 {
			compatible = "renesas,poeg-r9a07g076";
			reg = <0 0x080087800 0 0x400>;
			interrupts = <GIC_SPI 343 IRQ_TYPE_LEVEL_HIGH>;
			clocks = <&cpg CPG_CORE R9A07G076_PCLKL>;
			power-domains = <&cpg>;
			status = "disabled";
		};

		poeg1_d: poegd@080087c00 {
			compatible = "renesas,poeg-r9a07g076";
			reg = <0 0x080087c00 0 0x400>;
			interrupts = <GIC_SPI 344 IRQ_TYPE_LEVEL_HIGH>;
			clocks = <&cpg CPG_CORE R9A07G076_PCLKL>;
			power-domains = <&cpg>;
			status = "disabled";
		};

		poeg2_a: poega@8100a000 {
			compatible = "renesas,poeg-r9a07g076";
			reg = <0 0x8100a000 0 0x400>;
			interrupts = <GIC_SPI 345 IRQ_TYPE_LEVEL_HIGH>;
			clocks = <&cpg CPG_CORE R9A07G076_PCLKL>;
			power-domains = <&cpg>;
			status = "disabled";
		};

		poeg2_b: poegb@8100a400 {
			compatible = "renesas,poeg-r9a07g076";
			reg = <0 0x8100a400 0 0x400>;
			interrupts = <GIC_SPI 346 IRQ_TYPE_LEVEL_HIGH>;
			clocks = <&cpg CPG_CORE R9A07G076_PCLKL>;
			power-domains = <&cpg>;
			status = "disabled";
		};

		poeg2_c: poegc@8100a800 {
			compatible = "renesas,poeg-r9a07g076";
			reg = <0 0x8100a800 0 0x400>;
			interrupts = <GIC_SPI 347 IRQ_TYPE_LEVEL_HIGH>;
			clocks = <&cpg CPG_CORE R9A07G076_PCLKL>;
			power-domains = <&cpg>;
			status = "disabled";
		};

		poeg2_d: poegd@08100ac00 {
			compatible = "renesas,poeg-r9a07g076";
			reg = <0 0x8100ac00 0 0x400>;
			interrupts = <GIC_SPI 348 IRQ_TYPE_LEVEL_HIGH>;
			clocks = <&cpg CPG_CORE R9A07G076_PCLKL>;
			power-domains = <&cpg>;
			status = "disabled";
		};

		hpsw: hpsw@80170000 {
			compatible = "renesas,rzt2n-hpsw";
			reg = <0 0x80170000 0 0x50000>;
			clocks = <&cpg CPG_MOD R9A07G076_HPSW_CLK>;
			resets = <&cpg R9A07G076_HPSW_RST>;
			power-domains = <&cpg>;
			status = "disabled";

			ethernet-ports {
				#address-cells = <1>;
				#size-cells = <0>;

				hpsw_portA: port@0 {
					reg = <0>;
					status = "disabled";
				};

				hpsw_portB: port@1 {
					reg = <1>;
					status = "disabled";
				};

				hpsw_portC: port@2 {
					reg = <2>;
					ethernet = <&gmac0>;
					phy-mode = "internal";
					status = "disabled";
					fixed-link {
						speed = <1000>;
						full-duplex;
					};
				};
			};
		};

		edac: edac@80300000 {
			compatible = "renesas,r9a07g076-edac";
			reg = <0 0x80300000 0 0x10000>;
			interrupts = <GIC_SPI 629 IRQ_TYPE_LEVEL_HIGH>;
			interrupt-names = "ecc_irq";
		};
	};

	thermal-zones {
		emergency {
			polling-delay = <1000>;
			on-temperature = <110000>;
			off-temperature = <95000>;
			target_cpus = <&cpu1>;
			status = "disabled";
		};

		sensor_thermal: sensor-thermal {
			polling-delay-passive = <250>;
			polling-delay = <1000>;
			thermal-sensors = <&tsu 0>;

			trips {
				sensor_crit: sensor-crit {
					temperature = <123000>;
					hysteresis = <1000>;
					type = "critical";
				};
			};
		};
	};

	timer {
		compatible = "arm,armv8-timer";
		interrupts-extended = <&gic GIC_PPI 13 IRQ_TYPE_LEVEL_LOW>,
				      <&gic GIC_PPI 14 IRQ_TYPE_LEVEL_LOW>,
				      <&gic GIC_PPI 11 IRQ_TYPE_LEVEL_LOW>,
				      <&gic GIC_PPI 10 IRQ_TYPE_LEVEL_LOW>,
				      <&gic GIC_PPI 12 IRQ_TYPE_LEVEL_LOW>;
		interrupt-names = "sec-phys", "phys", "virt", "hyp-phys", "hyp-virt";
	};
};
